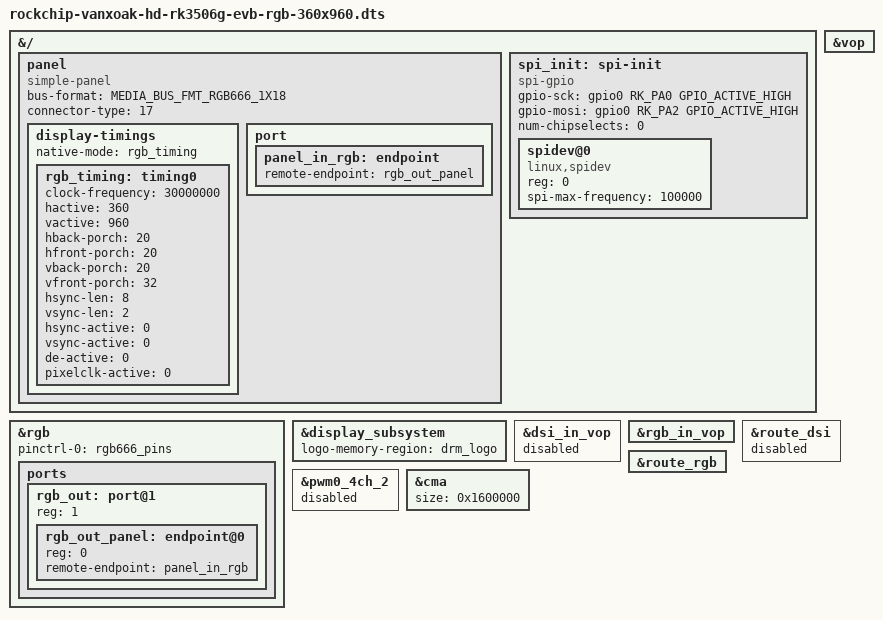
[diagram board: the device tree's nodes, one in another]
// SPDX-License-Identifier: (GPL-2.0+ OR MIT)
/*
 * Copyright (c) 2024 Rockchip Electronics Co., Ltd.
 * GC9503CV RGB panel with SPI init, 360x960
 */

/dts-v1/;
/plugin/;

#include <dt-bindings/display/media-bus-format.h>
#include <dt-bindings/gpio/gpio.h>
#include <dt-bindings/pinctrl/rockchip.h>

&{/} {
	panel: panel {
		compatible = "simple-panel";
		bus-format = <MEDIA_BUS_FMT_RGB666_1X18>;
		connector-type = <17>;
		status = "okay";

		display-timings {
			native-mode = <&rgb_timing>;

			rgb_timing: timing0 {
				clock-frequency = <30000000>;
				hactive = <360>;
				vactive = <960>;
				hback-porch = <20>;
				hfront-porch = <20>;
				vback-porch = <20>;
				vfront-porch = <32>;
				hsync-len = <8>;
				vsync-len = <2>;
				hsync-active = <0>;
				vsync-active = <0>;
				de-active = <0>;
				pixelclk-active = <0>;
			};
		};

		port {
			panel_in_rgb: endpoint {
				remote-endpoint = <&rgb_out_panel>;
			};
		};
	};

	spi_init: spi-init {
		compatible = "spi-gpio";
		#address-cells = <1>;
		#size-cells = <0>;
		gpio-sck = <&gpio0 RK_PA0 GPIO_ACTIVE_HIGH>;
		gpio-mosi = <&gpio0 RK_PA2 GPIO_ACTIVE_HIGH>;
		num-chipselects = <0>;
		status = "okay";

		spidev@0 {
			compatible = "linux,spidev";
			reg = <0>;
			spi-max-frequency = <100000>;
		};
	};
};

&rgb {
	status = "okay";
	pinctrl-names = "default";
	pinctrl-0 = <&rgb666_pins>;

	ports {
		rgb_out: port@1 {
			reg = <1>;
			#address-cells = <1>;
			#size-cells = <0>;

			rgb_out_panel: endpoint@0 {
				reg = <0>;
				remote-endpoint = <&panel_in_rgb>;
			};
		};
	};
};

&display_subsystem {
	status = "okay";
	logo-memory-region = <&drm_logo>;
};

&vop {
	status = "okay";
};

&dsi_in_vop {
	status = "disabled";
};

&rgb_in_vop {
	status = "okay";
};

&route_dsi {
	status = "disabled";
};

&route_rgb {
	status = "okay";
};

&pwm0_4ch_2 {
	status = "disabled";
};

&cma {
	size = <0x1600000>;
};
